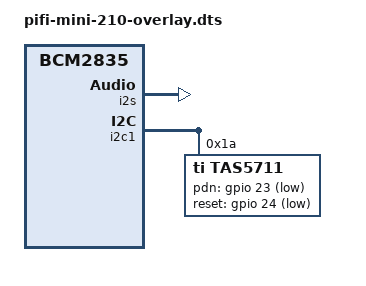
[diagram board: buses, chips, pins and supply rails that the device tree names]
// Definitions for PiFi Mini 210
/dts-v1/;
/plugin/;

/ {
	compatible = "brcm,bcm2835";

	fragment@0 {
		target = <&i2s>;
		__overlay__ {
			status = "okay";
		};
	};

	fragment@1 {
		target = <&i2c1>;
		__overlay__ {
			#address-cells = <1>;
			#size-cells = <0>;
			status = "okay";

			tas5711@1a {
				#sound-dai-cells = <0>;
				compatible = "ti,tas5711";
				reg = <0x1a>;
				status = "okay";
				pdn-gpios = <&gpio 23 1>;
				reset-gpios = <&gpio 24 1>;
			};
		};
	};

	fragment@2 {
		target = <&sound>;
		__overlay__ {
			compatible = "pifi,pifi-mini-210";
			i2s-controller = <&i2s>;

			status = "okay";
		};
	};
};
